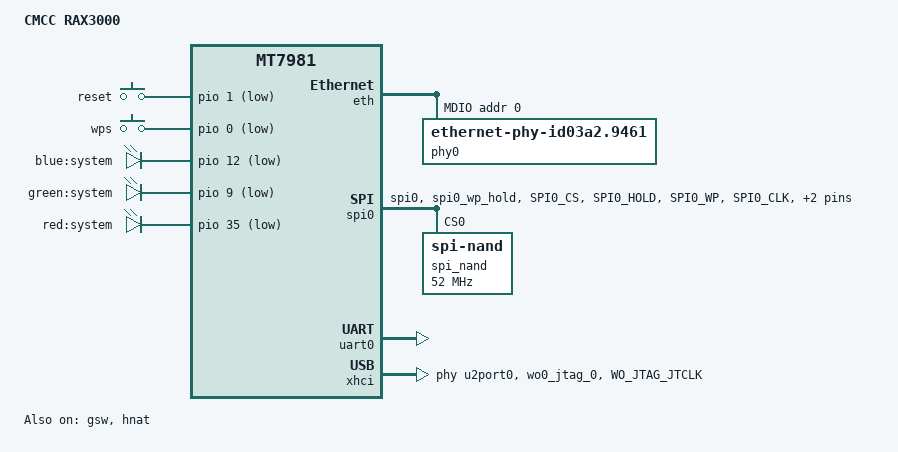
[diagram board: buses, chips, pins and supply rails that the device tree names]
// SPDX-License-Identifier: GPL-2.0-or-later OR MIT
/dts-v1/;

#include "mt7981.dtsi"

/ {
	model = "CMCC RAX3000";
	compatible = "cmcc,rax3000m", "mediatek,mt7981";

	aliases {
		led-boot = &led_system_blue;
		led-failsafe = &led_system_red;
		led-running = &led_system_blue;
		led-upgrade = &led_system_green;
	};

	chosen {
		bootargs = "console=ttyS0,115200n1 loglevel=8 \
			    earlycon=uart8250,mmio32,0x11002000";
	};

	gpio-keys {
		compatible = "gpio-keys";

		reset {
			label = "reset";
			linux,code = <KEY_RESTART>;
			gpios = <&pio 1 GPIO_ACTIVE_LOW>;
		};

		wps {
			label = "wps";
			linux,code = <KEY_WPS_BUTTON>;
			gpios = <&pio 0 GPIO_ACTIVE_LOW>;
		};
	};

	leds {
		compatible = "gpio-leds";

		led_system_blue: system_blue {
			label = "blue:system";
			gpios = <&pio 12 GPIO_ACTIVE_LOW>;
		};

		led_system_green: system_green {
			label = "green:system";
			gpios = <&pio 9 GPIO_ACTIVE_LOW>;
		};
		
		led_system_red: system_red {
			label = "red:system";
			gpios = <&pio 35 GPIO_ACTIVE_LOW>;
		};
	};

	nmbm_spim_nand {
		compatible = "generic,nmbm";
		#address-cells = <1>;
		#size-cells = <1>;

		lower-mtd-device = <&spi_nand>;
		max-reserved-blocks = <32>;
		forced-create;

		partitions {
			compatible = "fixed-partitions";
			#address-cells = <1>;
			#size-cells = <1>;

			partition@0 {
				label = "BL2";
				reg = <0x0000000 0x0100000>;
				read-only;
			};

			partition@100000 {
				label = "u-boot-env";
				reg = <0x0100000 0x0080000>;
			};

			partition@180000 {
				label = "Factory";
				reg = <0x0180000 0x0200000>;
				read-only;
			};

			partition@380000 {
				label = "FIP";
				reg = <0x0380000 0x0200000>;
				read-only;
			};

			partition@580000 {
				label = "ubi";
				reg = <0x0580000 0x7200000>;
			};
		};
	};
};

&eth {
	status = "okay";

	gmac0: mac@0 {
		compatible = "mediatek,eth-mac";
		reg = <0>;
		phy-mode = "2500base-x";

		fixed-link {
			speed = <2500>;
			full-duplex;
			pause;
		};
	};

	gmac1: mac@1 {
		compatible = "mediatek,eth-mac";
		reg = <1>;
		phy-mode = "gmii";
		phy-handle = <&phy0>;
	};

	mdio: mdio-bus {
		#address-cells = <1>;
		#size-cells = <0>;

		phy0: phy@0 {
			compatible = "ethernet-phy-id03a2.9461";
			reg = <0>;
			nvmem-cells = <&phy_calibration>;
			nvmem-cell-names = "phy-cal-data";
		};
	};
};

&gsw {
	mediatek,mdio = <&mdio>;
	mediatek,mdio_master_pinmux = <0>;
	reset-gpios = <&pio 39 0>;
	interrupt-parent = <&pio>;
	interrupts = <38 IRQ_TYPE_LEVEL_HIGH>;
	status = "okay";

	port6: port@6 {
		compatible = "mediatek,mt753x-port";
		mediatek,ssc-on;
		reg = <6>;
		phy-mode = "sgmii";

		fixed-link {
			speed = <2500>;
			full-duplex;
		};
	};
};

&hnat {
	mtketh-wan = "eth1";
	mtketh-lan = "lan";
	mtketh-max-gmac = <2>;
	mtketh-ppe-num = <2>;
	status = "okay";
};

&spi0 {
	pinctrl-names = "default";
	pinctrl-0 = <&spi0_flash_pins>;
	status = "okay";

	spi_nand: spi_nand@0 {
		compatible = "spi-nand";
		#address-cells = <1>;
		#size-cells = <1>;
		reg = <0>;

		spi-max-frequency = <52000000>;
		spi-tx-buswidth = <4>;
		spi-rx-buswidth = <4>;
	};
};

&pio {
	usb_pwr_pins: usb-pins {
		mux {
			function = "jtag";
			groups = "wo0_jtag_0";
		};

		power {
			pins = "WO_JTAG_JTCLK";
			drive-strength = <MTK_DRIVE_8mA>;
			mediatek,pull-up-adv = <1>;
		};
	};

	spi0_flash_pins: spi0-pins {
		mux {
			function = "spi";
			groups = "spi0", "spi0_wp_hold";
		};

		conf-pu {
			pins = "SPI0_CS", "SPI0_HOLD", "SPI0_WP";
			drive-strength = <MTK_DRIVE_8mA>;
			bias-pull-up = <MTK_PUPD_SET_R1R0_11>;
		};

		conf-pd {
			pins = "SPI0_CLK", "SPI0_MOSI", "SPI0_MISO";
			drive-strength = <MTK_DRIVE_8mA>;
			bias-pull-down = <MTK_PUPD_SET_R1R0_11>;
		};
	};
};

&uart0 {
	status = "okay";
};

&xhci {
	mediatek,u3p-dis-msk = <0x0>;
	phys = <&u2port0 PHY_TYPE_USB2>,
	       <&u3port0 PHY_TYPE_USB3>;
	pinctrl-0 = <&usb_pwr_pins>;
	pinctrl-names = "default";
	status = "okay";
};
